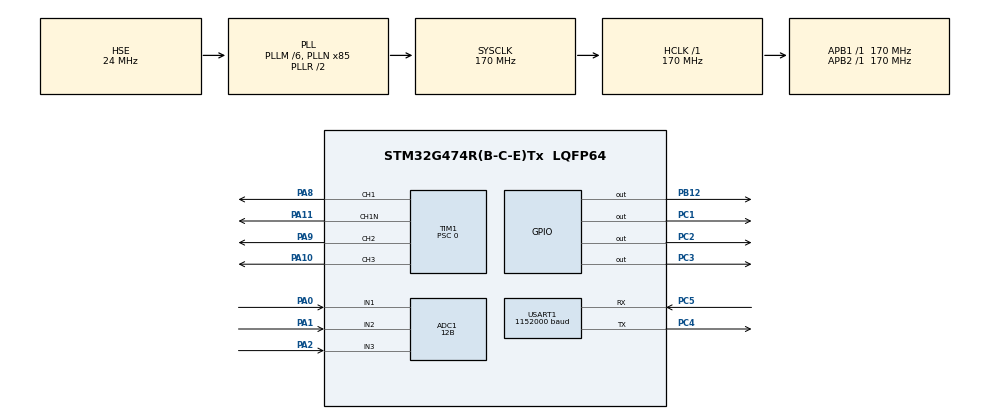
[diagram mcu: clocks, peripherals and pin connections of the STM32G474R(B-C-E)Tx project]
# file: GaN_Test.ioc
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ADC1.Channel-10\#ChannelRegularConversion=ADC_CHANNEL_3
ADC1.Channel-4\#ChannelRegularConversion=ADC_CHANNEL_1
ADC1.Channel-9\#ChannelRegularConversion=ADC_CHANNEL_2
ADC1.DMAContinuousRequests=ENABLE
ADC1.DiscontinuousConvMode=DISABLE
ADC1.EOCSelection=ADC_EOC_SEQ_CONV
ADC1.ExternalTrigConv=ADC_EXTERNALTRIG_T1_TRGO
ADC1.ExternalTrigConvEdge=ADC_EXTERNALTRIGCONVEDGE_RISING
ADC1.NbrOfConversion=3
ADC1.NbrOfConversionFlag=1
ADC1.OffsetNumber-10\#ChannelRegularConversion=ADC_OFFSET_NONE
ADC1.OffsetNumber-4\#ChannelRegularConversion=ADC_OFFSET_NONE
ADC1.OffsetNumber-9\#ChannelRegularConversion=ADC_OFFSET_NONE
ADC1.Rank-10\#ChannelRegularConversion=3
ADC1.Rank-4\#ChannelRegularConversion=1
ADC1.Rank-9\#ChannelRegularConversion=2
ADC1.Resolution=ADC_RESOLUTION_12B
ADC1.SamplingTime-10\#ChannelRegularConversion=ADC_SAMPLETIME_6CYCLES_5
ADC1.SamplingTime-4\#ChannelRegularConversion=ADC_SAMPLETIME_6CYCLES_5
ADC1.SamplingTime-9\#ChannelRegularConversion=ADC_SAMPLETIME_6CYCLES_5
ADC1.master=1
Dma.ADC1.0.Direction=DMA_PERIPH_TO_MEMORY
Dma.ADC1.0.EventEnable=DISABLE
Dma.ADC1.0.Instance=DMA1_Channel1
Dma.ADC1.0.MemDataAlignment=DMA_MDATAALIGN_HALFWORD
Dma.ADC1.0.MemInc=DMA_MINC_ENABLE
Dma.ADC1.0.Mode=DMA_CIRCULAR
Dma.ADC1.0.PeriphDataAlignment=DMA_PDATAALIGN_HALFWORD
Dma.ADC1.0.PeriphInc=DMA_PINC_DISABLE
Dma.ADC1.0.Polarity=HAL_DMAMUX_REQ_GEN_RISING
Dma.ADC1.0.Priority=DMA_PRIORITY_VERY_HIGH
Dma.ADC1.0.RequestNumber=1
Dma.ADC1.0.SignalID=NONE
Dma.ADC1.0.SyncEnable=DISABLE
Dma.ADC1.0.SyncPolarity=HAL_DMAMUX_SYNC_NO_EVENT
Dma.ADC1.0.SyncRequestNumber=1
Dma.ADC1.0.SyncSignalID=NONE
Dma.Request0=ADC1
Dma.Request1=USART1_TX
Dma.USART1_TX.1.Direction=DMA_MEMORY_TO_PERIPH
Dma.USART1_TX.1.EventEnable=DISABLE
Dma.USART1_TX.1.Instance=DMA1_Channel2
Dma.USART1_TX.1.MemDataAlignment=DMA_MDATAALIGN_BYTE
Dma.USART1_TX.1.MemInc=DMA_MINC_ENABLE
Dma.USART1_TX.1.Mode=DMA_CIRCULAR
Dma.USART1_TX.1.PeriphDataAlignment=DMA_PDATAALIGN_BYTE
Dma.USART1_TX.1.PeriphInc=DMA_PINC_DISABLE
Dma.USART1_TX.1.Polarity=HAL_DMAMUX_REQ_GEN_RISING
Dma.USART1_TX.1.Priority=DMA_PRIORITY_HIGH
Dma.USART1_TX.1.RequestNumber=1
Dma.USART1_TX.1.SignalID=NONE
Dma.USART1_TX.1.SyncEnable=DISABLE
Dma.USART1_TX.1.SyncPolarity=HAL_DMAMUX_SYNC_NO_EVENT
Dma.USART1_TX.1.SyncRequestNumber=1
Dma.USART1_TX.1.SyncSignalID=NONE
Mcu.Family=STM32G4
Mcu.Name=STM32G474R(B-C-E)Tx
Mcu.Package=LQFP64
Mcu.UserConstants=MASTER_PERIOD,(340);TIM_PERIOD,(MASTER_PERIOD/2);TIM_A_DUTY,(0.5f);TIM_B_DUTY,(0.25f);DEADTIME,(10);TIM_C_DUTY,(0.1f)
NVIC.DMA1_Channel1_IRQn=true\:1\:1\:true\:false\:true\:true\:false\:true
NVIC.PriorityGroup=NVIC_PRIORITYGROUP_3
NVIC.TIM1_UP_TIM16_IRQn=true\:0\:0\:false\:false\:true\:true\:false\:true
PA0.Mode=IN1-Single-Ended
PA0.Signal=ADC1_IN1
PA1.Mode=IN2-Single-Ended
PA1.Signal=ADC1_IN2
PA10.GPIO_Speed=GPIO_SPEED_FREQ_VERY_HIGH
PA10.Signal=S_TIM1_CH3
PA11.GPIO_Speed=GPIO_SPEED_FREQ_VERY_HIGH
PA11.Mode=PWM Generation1 CH1 CH1N
PA11.Signal=TIM1_CH1N
PA2.Mode=IN3-Single-Ended
PA2.Signal=ADC1_IN3
PA8.GPIO_Speed=GPIO_SPEED_FREQ_VERY_HIGH
PA8.Signal=S_TIM1_CH1
PA9.GPIO_Speed=GPIO_SPEED_FREQ_VERY_HIGH
PA9.Signal=S_TIM1_CH2
PB12.Signal=GPIO_Output
PC1.GPIO_Speed=GPIO_SPEED_FREQ_VERY_HIGH
PC1.PinState=GPIO_PIN_SET
PC1.Signal=GPIO_Output
PC2.GPIO_Speed=GPIO_SPEED_FREQ_VERY_HIGH
PC2.PinState=GPIO_PIN_SET
PC2.Signal=GPIO_Output
PC3.GPIO_Speed=GPIO_SPEED_FREQ_VERY_HIGH
PC3.Signal=GPIO_Output
PC4.GPIO_Speed=GPIO_SPEED_FREQ_VERY_HIGH
PC4.Mode=Asynchronous
PC4.Signal=USART1_TX
PC5.GPIO_Speed=GPIO_SPEED_FREQ_VERY_HIGH
PC5.Mode=Asynchronous
PC5.Signal=USART1_RX
PF0-OSC_IN.Mode=HSE-External-Oscillator
PF0-OSC_IN.Signal=RCC_OSC_IN
PF1-OSC_OUT.Mode=HSE-External-Oscillator
PF1-OSC_OUT.Signal=RCC_OSC_OUT
ProjectManager.HeapSize=0x200
ProjectManager.StackSize=0x400
ProjectManager.TargetToolchain=MDK-ARM V5.32
RCC.ADC12Freq_Value=170000000
RCC.ADC345Freq_Value=170000000
RCC.AHBFreq_Value=170000000
RCC.APB1Freq_Value=170000000
RCC.APB1TimFreq_Value=170000000
RCC.APB2Freq_Value=170000000
RCC.APB2TimFreq_Value=170000000
RCC.CortexFreq_Value=170000000
RCC.EXTERNAL_CLOCK_VALUE=12288000
RCC.HCLKFreq_Value=170000000
RCC.HSE_VALUE=24000000
RCC.HSI48_VALUE=48000000
RCC.HSI_VALUE=16000000
RCC.LSE_VALUE=32768
RCC.PLLM=RCC_PLLM_DIV6
RCC.PLLN=85
RCC.PLLSourceVirtual=RCC_PLLSOURCE_HSE
RCC.SYSCLKFreq_VALUE=170000000
RCC.SYSCLKSource=RCC_SYSCLKSOURCE_PLLCLK
RCC.USBFreq_Value=170000000
RCC.VCOOutputFreq_Value=340000000
SH.S_TIM1_CH1.0=TIM1_CH1,PWM Generation1 CH1 CH1N
SH.S_TIM1_CH2.0=TIM1_CH2,PWM Generation2 CH2
SH.S_TIM1_CH3.0=TIM1_CH3,PWM Generation3 CH3
TIM1.AutomaticOutput=TIM_AUTOMATICOUTPUT_ENABLE
TIM1.Channel-PWM\ Generation1\ CH1\ CH1N=TIM_CHANNEL_1
TIM1.Channel-PWM\ Generation2\ CH2=TIM_CHANNEL_2
TIM1.Channel-PWM\ Generation3\ CH3=TIM_CHANNEL_3
TIM1.CounterMode=TIM_COUNTERMODE_CENTERALIGNED2
TIM1.DeadTime=DEADTIME
TIM1.OCMode_PWM-PWM\ Generation1\ CH1\ CH1N=TIM_OCMODE_PWM1
TIM1.OCMode_PWM-PWM\ Generation2\ CH2=TIM_OCMODE_PWM1
TIM1.OCMode_PWM-PWM\ Generation3\ CH3=TIM_OCMODE_PWM1
TIM1.OCPolarity_2=TIM_OCPOLARITY_HIGH
TIM1.OCPolarity_3=TIM_OCPOLARITY_HIGH
TIM1.OffStateIDLEMode=TIM_OSSI_ENABLE
TIM1.OffStateRunMode=TIM_OSSR_ENABLE
TIM1.PeriodNoDither=(TIM_PERIOD-1)
TIM1.Prescaler=0
TIM1.PulseNoDither_1=(TIM_PERIOD*TIM_C_DUTY)
TIM1.PulseNoDither_2=(TIM_PERIOD*TIM_B_DUTY)
TIM1.PulseNoDither_3=(TIM_PERIOD*TIM_A_DUTY)
TIM1.TIM_MasterOutputTrigger=TIM_TRGO_UPDATE
USART1.BaudRate=1152000
USART1.VirtualMode-Asynchronous=VM_ASYNC
VP_SYS_VS_DBSignals.Mode=DisableDeadBatterySignals
VP_TIM1_VS_ClockSourceINT.Mode=Internal
board=custom

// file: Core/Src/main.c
/* USER CODE BEGIN Header */
/**
  ******************************************************************************
  * @file           : main.c
  * @brief          : Main program body
  ******************************************************************************
  * @attention
  *
  * Copyright (c) 2024 STMicroelectronics.
  * All rights reserved.
  *
  * This software is licensed under terms that can be found in the LICENSE file
  * in the root directory of this software component.
  * If no LICENSE file comes with this software, it is provided AS-IS.
  *
  ******************************************************************************
  */
/* USER CODE END Header */
#include "main.h"
#include "adc.h"
#include "dma.h"
#include "tim.h"
#include "usart.h"
#include "gpio.h"

/* USER CODE BEGIN PV */
extern DMA_HandleTypeDef hdma_adc1;
/* USER CODE END PV */

void SystemClock_Config(void);

/* USER CODE BEGIN 0 */
uint16_t i;
#define ADC1_CHANNEL_CNT 3 	//
uint16_t adc1_val_buf[ADC1_CHANNEL_CNT]; //
//uint32_t adc1_aver_val[ADC1_CHANNEL_CNT] = {0}; 					//
//uint16_t value[ADC1_CHANNEL_CNT] = {0};										//

///* VOFA */
//#define CH_COUNT 		2
//#define FRAME_COUNT 1
//struct FOFA_Frame {
//	float fdata[CH_COUNT];		//float 32  4byte
//	uint8_t tail[4];
//};
//struct FOFA_Frame UART_FRAME[FRAME_COUNT] = {
//	{0,0x00,0x00,0x80,0x7f}
//};

/* USER CODE END 0 */

int main(void)
{

  /* MCU Configuration--------------------------------------------------------*/

  /* Reset of all peripherals, Initializes the Flash interface and the Systick. */
  HAL_Init();

  /* Configure the system clock */
  SystemClock_Config();

  /* Initialize all configured peripherals */
  MX_GPIO_Init();
  MX_DMA_Init();
  MX_ADC1_Init();
  MX_USART1_UART_Init();
  MX_TIM1_Init();
  /* USER CODE BEGIN 2 */

//	HAL_Delay(50000);

	HAL_TIM_PWM_Start(&htim1,TIM_CHANNEL_1);
	HAL_TIMEx_PWMN_Start(&htim1,TIM_CHANNEL_1);
	HAL_TIM_PWM_Start(&htim1,TIM_CHANNEL_2);
	HAL_TIM_PWM_Start(&htim1,TIM_CHANNEL_3);

	HAL_TIM_Base_Start_IT(&htim1);		//开启定时器中断，在main函数里面初始化

	HAL_ADC_Start_DMA(&hadc1, (uint32_t*)&adc1_val_buf, (ADC1_CHANNEL_CNT*1));
	//HAL_ADC_Start_IT(&hadc1);
	//close DMA all interrupt
	//__HAL_DMA_DISABLE_IT(&hdma_adc1, (DMA_IT_TC| DMA_IT_HT | DMA_IT_TE));
	//close DMA Half transfer complete interrupt
	__HAL_DMA_DISABLE_IT(&hdma_adc1, (DMA_IT_HT | DMA_IT_TE));

	/**	Notices (ToDo
		* ADC sampling location
	  * 	change adc trigger location hrtim.c pCompareCfg.CompareValue = MASTER_PERIOD;
		* 	MASTER_PERIOD -> H    MASTER_PERIOD*0.5 -> L
		* 	MASTER_UPDATA -> H
	  * 	debug note hrtim amd dma nvic HAL_NVIC_SetPriority
	  */
  /* USER CODE END 2 */

  /* Infinite loop */
  /* USER CODE BEGIN WHILE */
	//uint16_t i = 0;

//	for(i = 0; i < 1000; i++)
//	{
//		UART_FRAME[i].tail[0]=0x00;
//		UART_FRAME[i].tail[1]=0x00;
//		UART_FRAME[i].tail[2]=0x80;
//		UART_FRAME[i].tail[3]=0x7f;
//	}
	//hhrtim1.Instance->sTimerxRegs[0].CMP1xR = 85;
	//__HAL_HRTIM_SETCOMPARE(&hhrtim1, HRTIM_TIMERINDEX_TIMER_A, HRTIM_COMPAREUNIT_1, 85);

  while (1)
  {
    /* USER CODE END WHILE */

  }
}

void SystemClock_Config(void)
{
  RCC_OscInitTypeDef RCC_OscInitStruct = {0};
  RCC_ClkInitTypeDef RCC_ClkInitStruct = {0};

  /** Configure the main internal regulator output voltage
  */
  HAL_PWREx_ControlVoltageScaling(PWR_REGULATOR_VOLTAGE_SCALE1_BOOST);

  /** Initializes the RCC Oscillators according to the specified parameters
  * in the RCC_OscInitTypeDef structure.
  */
  RCC_OscInitStruct.OscillatorType = RCC_OSCILLATORTYPE_HSE;
  RCC_OscInitStruct.HSEState = RCC_HSE_ON;
  RCC_OscInitStruct.PLL.PLLState = RCC_PLL_ON;
  RCC_OscInitStruct.PLL.PLLSource = RCC_PLLSOURCE_HSE;
  RCC_OscInitStruct.PLL.PLLM = RCC_PLLM_DIV6;
  RCC_OscInitStruct.PLL.PLLN = 85;
  RCC_OscInitStruct.PLL.PLLP = RCC_PLLP_DIV2;
  RCC_OscInitStruct.PLL.PLLQ = RCC_PLLQ_DIV2;
  RCC_OscInitStruct.PLL.PLLR = RCC_PLLR_DIV2;
  if (HAL_RCC_OscConfig(&RCC_OscInitStruct) != HAL_OK)
  {
    Error_Handler();
  }

  /** Initializes the CPU, AHB and APB buses clocks
  */
  RCC_ClkInitStruct.ClockType = RCC_CLOCKTYPE_HCLK|RCC_CLOCKTYPE_SYSCLK
                              |RCC_CLOCKTYPE_PCLK1|RCC_CLOCKTYPE_PCLK2;
  RCC_ClkInitStruct.SYSCLKSource = RCC_SYSCLKSOURCE_PLLCLK;
  RCC_ClkInitStruct.AHBCLKDivider = RCC_SYSCLK_DIV1;
  RCC_ClkInitStruct.APB1CLKDivider = RCC_HCLK_DIV1;
  RCC_ClkInitStruct.APB2CLKDivider = RCC_HCLK_DIV1;

  if (HAL_RCC_ClockConfig(&RCC_ClkInitStruct, FLASH_LATENCY_4) != HAL_OK)
  {
    Error_Handler();
  }
}

void Error_Handler(void)
{
  __disable_irq();
  while (1)
  {
  }
}
